# PIC32CM2532LE00048 register map
Vendor: Microchip Technology; Series: PIC32CMLE00; File version: 0
Microchip PIC32CM2532LE00048 Microcontroller
CPU: CM23 r0p0, selectable endian, MPU, no FPU, 2 interrupt priority bits
Registers are 32-bit, read-write, reset 0x0 unless marked. A register's access mark holds for its fields unless they carry their own. Offsets are from the block's base; lines under a group give offsets from that group; [hi:lo] are bit positions; {n}, {i} and the like mark numbered series; 'fields as' and 'values as' point back to an identical list; <NAME> marks a mode.

## Memory map
0x40000000 PAC size 0x40 — Peripheral Access Controller
0x40000400 PM size 0xA — Power Manager
0x40000800 MCLK size 0x20 — Main Clock
0x40000C00 RSTC size 0x1 — Reset Controller
0x40001000 OSCCTRL size 0x55 — Oscillators Control
0x40001400 OSC32KCTRL size 0x20 — 32k Oscillators Control
0x40001800 SUPC size 0x30 — Supply Controller
0x40001C00 GCLK size 0x154 — Generic Clock Generator
0x40002000 WDT size 0xD — Watchdog Timer
0x40002400 RTC size 0x70 — Real-Time Counter
0x40002800 EIC size 0x3C — External Interrupt Controller
0x40002C00 FREQM size 0x14 — Frequency Meter
0x40003000 PORT size 0x100 — Port Module
0x40003400 AC size 0x24 — Analog Comparators
0x41002000 DSU size 0x2000 — Device Service Unit
0x41002100 DSU_EXT size 0x2000
0x41004000 NVMCTRL size 0x40 — Non-Volatile Memory Controller
0x41006000 DMAC size 0x50 — Direct Memory Access Controller
0x4100A000 USB size 0x200 — Universal Serial Bus
0x42000000 EVSYS size 0x172 — Event System Interface
0x42000400 SERCOM0 size 0x38 — Serial Communication Interface
0x42000800 SERCOM1 size 0x38
0x42000C00 SERCOM2 size 0x38
0x42001000 SERCOM3 size 0x38
0x42001400 SERCOM4 size 0x38
0x42001800 SERCOM5 size 0x38
0x42001C00 TC0 size 0x38 — Basic Timer Counter
0x42002000 TC1 size 0x38
0x42002400 TC2 size 0x38
0x42002800 TCC0 size 0x80 — Timer Counter for Control Applications
0x42002C00 TCC1 size 0x80
0x42003000 TCC2 size 0x80
0x42003400 TCC3 size 0x80
0x42003800 ADC size 0x2E — Analog Digital Converter
0x42003C00 DAC size 0x19 — Digital-to-Analog Converter
0x42004000 PTC — Peripheral Touch Controller
0x42004400 TRNG size 0x24 — True Random Generator
0x42004800 CCL size 0x18 — Configurable Custom Logic
0x42004C00 I2S size 0x38 — Inter-IC Sound Interface
0x42005000 OPAMP size 0x11 — Operational Amplifier
0x42005400 TRAM size 0x6A0 — TrustRAM
0x60000000 PORT_IOBUS size 0x100
0xE0001000 DWT size 0x1000 — Data Watchpoint and Trace
0xE0002000 FPB size 0x1000 — Flash Patch and Breakpoint
0xE000E000 ICB size 0xC — Implementation Control Block
0xE000E010 SysTick size 0x10 — SysTick Timer
0xE000E100 NVIC size 0x360 — Nested Vectored Interrupt Controller
0xE000ED00 SCB size 0x88 — System Control Block
0xE000ED90 MPU size 0x38 — Memory Protection Unit
0xE000EDF0 CoreDebug size 0x1C — Debug Control Block
0xE000EFB0 DIB size 0x50 — Debug Identification Block

## Interrupts
1 WDT
2 RTC
{n+3} EIC_EXTINT_{n} (EIC) (n=0..7)
11 EIC_OTHER (EIC)
12 FREQM
13 NVMCTRL
15 DMAC_0 (DMAC)
16 DMAC_1 (DMAC)
17 DMAC_2 (DMAC)
18 DMAC_3 (DMAC)
19 DMAC_OTHER (DMAC)
20 USB
{n+21} EVSYS_{n} (EVSYS) (n=0..7)
30 PAC
31 SERCOM0_0 (SERCOM0)
32 SERCOM0_1 (SERCOM0)
33 SERCOM0_2 (SERCOM0)
34 SERCOM0_OTHER (SERCOM0)
35 SERCOM1_0 (SERCOM1)
36 SERCOM1_1 (SERCOM1)
37 SERCOM1_2 (SERCOM1)
38 SERCOM1_OTHER (SERCOM1)
39 SERCOM2_0 (SERCOM2)
40 SERCOM2_1 (SERCOM2)
41 SERCOM2_2 (SERCOM2)
42 SERCOM2_OTHER (SERCOM2)
43 SERCOM3_0 (SERCOM3)
44 SERCOM3_1 (SERCOM3)
45 SERCOM3_2 (SERCOM3)
46 SERCOM3_OTHER (SERCOM3)
47 SERCOM4_0 (SERCOM4)
48 SERCOM4_1 (SERCOM4)
49 SERCOM4_2 (SERCOM4)
50 SERCOM4_OTHER (SERCOM4)
51 SERCOM5_0 (SERCOM5)
52 SERCOM5_1 (SERCOM5)
53 SERCOM5_2 (SERCOM5)
54 SERCOM5_OTHER (SERCOM5)
55 TC0
56 TC1
57 TC2
58 TCC0
59 TCC1
60 TCC2
61 TCC3
62 ADC_OTHER (ADC)
63 ADC_RESRDY (ADC)
64 AC
65 DAC_UNDERRUN (DAC)
66 DAC_EMPTY (DAC)
67 PTC
68 TRNG
69 I2S
70 TRAM

## CCL — Configurable Custom Logic
Base 0x42004800; register names take the prefix CCL_
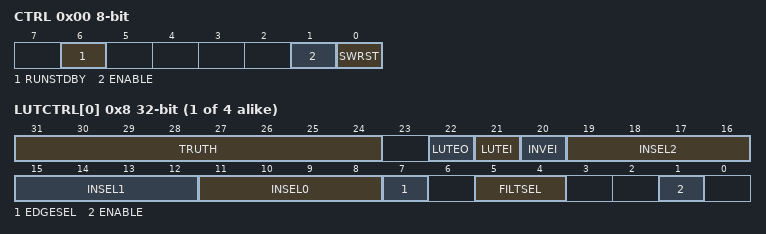
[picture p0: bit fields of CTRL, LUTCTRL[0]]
0x00 CTRL 8-bit — Control
  [6] RUNSTDBY — Run in Standby
    0=DISABLE (Generic clock is not required in standby sleep mode); 1=ENABLE (Generic clock is required in standby sleep mode)
  [1] ENABLE
    0=DISABLE (The peripheral is disabled); 1=ENABLE (The peripheral is enabled)
  [0] SWRST — Software Reset
    0=DISABLE (The peripheral is not reset); 1=ENABLE (The peripheral is reset)
{0x4+i} SEQCTRL[{i}] (i=0..1) 8-bit — SEQ Control x
  [3:0] SEQSEL — Sequential Selection
    0=DISABLE (Sequential logic is disabled); 1=DFF (D flip flop); 2=JK (JK flip flop); 3=LATCH (D latch); 4=RS (RS latch)
{0x8+4i} LUTCTRL[{i}] (i=0..3) — LUT Control x
  [31:24] TRUTH — Truth Value
  [22] LUTEO — LUT Event Output Enable
    0=DISABLE (LUT event output is disabled); 1=ENABLE (LUT event output is enabled)
  [21] LUTEI — LUT Event Input Enable
    0=DISABLE (LUT incoming event is disabled); 1=ENABLE (LUT incoming event is enabled)
  [20] INVEI — Inverted Event Input Enable
    0=NORMAL (Incoming event is not inverted); 1=INVERTED (Incoming event is inverted)
  [19:16] INSEL2 — Input Selection 2
    0=MASK (Masked input); 1=FEEDBACK (Feedback input source); 2=LINK (Linked LUT input source); 3=EVENT (Event input source); 4=IO (I/O pin input source); 5=AC (AC input source); 6=TC (TC input source); 7=ALTTC (Alternate TC input source); 8=TCC (TCC input source); 9=SERCOM (SERCOM input source); 11=ASYNCEVENT (Asynchronous event input source)
  [15:12] INSEL1 — Input Selection 1
    values as INSEL2
  [11:8] INSEL0 — Input Selection 0
    values as INSEL2
  [7] EDGESEL — Edge Selection
    0=DISABLE (Edge detector is disabled); 1=ENABLE (Edge detector is enabled)
  [5:4] FILTSEL — Filter Selection
    0=DISABLE (Filter disabled); 1=SYNCH (Synchronizer enabled); 2=FILTER (Filter enabled)
  [1] ENABLE — LUT Enable
    0=DISABLE (LUT block is disabled); 1=ENABLE (LUT block is enabled)

## Notices in the file
Copyright (c) 2017 Microchip Technology Inc.
SPDX-License-Identifier: Apache-2.0
Licensed under the Apache License, Version 2.0 (the "License");
you may not use this file except in compliance with the License.
You may obtain a copy of the License at
http://www.apache.org/licenses/LICENSE-2.0
Unless required by applicable law or agreed to in writing, software
distributed under the License is distributed on an "AS IS" BASIS,
WITHOUT WARRANTIES OR CONDITIONS OF ANY KIND, either express or implied.
See the License for the specific language governing permissions and
limitations under the License.
